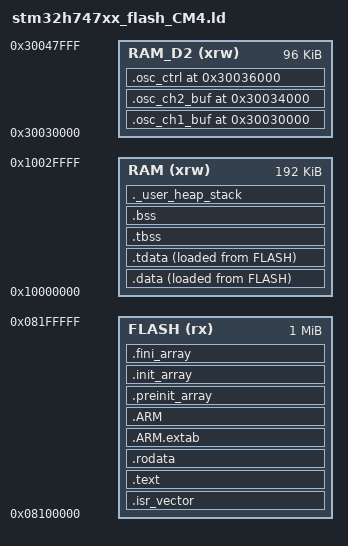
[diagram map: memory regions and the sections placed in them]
/*
******************************************************************************
**

**  File        : LinkerScript.ld
**
**
**  Abstract    : Linker script for STM32H7 series
**                1024Kbytes FLASH and 288Kbytes RAM
**
**                Set heap size, stack size and stack location according
**                to application requirements.
**
**                Set memory bank area and size if external memory is used.
**
**  Target      : STMicroelectronics STM32
**
**  Distribution: The file is distributed as is without any warranty
**                of any kind.
**
*****************************************************************************
** @attention
**
** Copyright (c) 2019 STMicroelectronics.
** All rights reserved.
**
** This software is licensed under terms that can be found in the LICENSE file
** in the root directory of this software component.
** If no LICENSE file comes with this software, it is provided AS-IS.
**
******************************************************************************
*/

/* Entry Point */
ENTRY(Reset_Handler)


/* Specify the memory areas */
MEMORY
{
FLASH (rx)      : ORIGIN = 0x08100000, LENGTH = 1024K
RAM (xrw)      : ORIGIN = 0x10000000, LENGTH = 192K
RAM_D2 (xrw)    : ORIGIN = 0x30030000, LENGTH = 96K
}
/* Highest address of the user mode stack */
_estack = 0x10030000;    /* end of RAM */
/* Generate a link error if heap and stack don't fit into RAM */
_Min_Heap_Size = 0x200;      /* required amount of heap  */
_Min_Stack_Size = 0x400; /* required amount of stack */

/* Define output sections */
SECTIONS
{
  /* The startup code goes first into FLASH */
  .isr_vector :
  {
    . = ALIGN(4);
    KEEP(*(.isr_vector)) /* Startup code */
    . = ALIGN(4);
  } >FLASH

  /* The program code and other data goes into FLASH */
  .text :
  {
    . = ALIGN(4);
    *(.text)           /* .text sections (code) */
    *(.text*)          /* .text* sections (code) */
    *(.glue_7)         /* glue arm to thumb code */
    *(.glue_7t)        /* glue thumb to arm code */
    *(.eh_frame)

    KEEP (*(.init))
    KEEP (*(.fini))

    . = ALIGN(4);
    _etext = .;        /* define a global symbols at end of code */
  } >FLASH

  /* Constant data goes into FLASH */
  .rodata :
  {
    . = ALIGN(4);
    *(.rodata)         /* .rodata sections (constants, strings, etc.) */
    *(.rodata*)        /* .rodata* sections (constants, strings, etc.) */
    . = ALIGN(4);
  } >FLASH

  .ARM.extab (READONLY) : /* The READONLY keyword is only supported in GCC11 and later, remove it if using GCC10 or earlier. */
  {
    *(.ARM.extab* .gnu.linkonce.armextab.*)
  } >FLASH
  .ARM (READONLY) : /* The READONLY keyword is only supported in GCC11 and later, remove it if using GCC10 or earlier. */
  {
    __exidx_start = .;
    *(.ARM.exidx*)
    __exidx_end = .;
  } >FLASH

  .preinit_array (READONLY) : /* The READONLY keyword is only supported in GCC11 and later, remove it if using GCC10 or earlier. */
  {
    PROVIDE_HIDDEN (__preinit_array_start = .);
    KEEP (*(.preinit_array*))
    PROVIDE_HIDDEN (__preinit_array_end = .);
  } >FLASH
  .init_array (READONLY) : /* The READONLY keyword is only supported in GCC11 and later, remove it if using GCC10 or earlier. */
  {
    PROVIDE_HIDDEN (__init_array_start = .);
    KEEP (*(SORT(.init_array.*)))
    KEEP (*(.init_array*))
    PROVIDE_HIDDEN (__init_array_end = .);
  } >FLASH
  .fini_array (READONLY) : /* The READONLY keyword is only supported in GCC11 and later, remove it if using GCC10 or earlier. */
  {
    PROVIDE_HIDDEN (__fini_array_start = .);
    KEEP (*(SORT(.fini_array.*)))
    KEEP (*(.fini_array*))
    PROVIDE_HIDDEN (__fini_array_end = .);
  } >FLASH

  /* used by the startup to initialize data */
  _sidata = LOADADDR(.data);

  /* Initialized data sections goes into RAM, load LMA copy after code */
  .data : 
  {
    . = ALIGN(4);
    _sdata = .;        /* create a global symbol at data start */
    *(.data)           /* .data sections */
    *(.data*)          /* .data* sections */

    . = ALIGN(4);
  } >RAM AT> FLASH

  /* Initialized TLS data section */
  .tdata : ALIGN(4)
  {
    *(.tdata .tdata.* .gnu.linkonce.td.*)
    . = ALIGN(4);
    _edata = .;        /* define a global symbol at data end */
    PROVIDE(__data_end = .);
    PROVIDE(__tdata_end = .);
  } >RAM AT> FLASH

  PROVIDE( __tdata_start = ADDR(.tdata) );
  PROVIDE( __tdata_size = __tdata_end - __tdata_start );

  PROVIDE( __data_start = ADDR(.data) );
  PROVIDE( __data_size = __data_end - __data_start );

  PROVIDE( __tdata_source = LOADADDR(.tdata) );
  PROVIDE( __tdata_source_end = LOADADDR(.tdata) + SIZEOF(.tdata) );
  PROVIDE( __tdata_source_size = __tdata_source_end - __tdata_source );

  PROVIDE( __data_source = LOADADDR(.data) );
  PROVIDE( __data_source_end = __tdata_source_end );
  PROVIDE( __data_source_size = __data_source_end - __data_source );


  
  /* Uninitialized data section */
  /* Uninitialized TLS data section */
  .tbss (NOLOAD) : ALIGN(4)
  {
    _sbss = .;         /* define a global symbol at bss start */
    __bss_start__ = _sbss;
    *(.tbss .tbss.*)
    . = ALIGN(4);
    PROVIDE( __tbss_end = . );
  } >RAM

  PROVIDE( __tbss_start = ADDR(.tbss) );
  PROVIDE( __tbss_size = __tbss_end - __tbss_start );
  PROVIDE( __tbss_offset = ADDR(.tbss) - ADDR(.tdata) );

  PROVIDE( __tls_base = __tdata_start );
  PROVIDE( __tls_end = __tbss_end );
  PROVIDE( __tls_size = __tls_end - __tls_base );
  PROVIDE( __tls_align = MAX(ALIGNOF(.tdata), ALIGNOF(.tbss)) );
  PROVIDE( __tls_size_align = (__tls_size + __tls_align - 1) & ~(__tls_align - 1) );
  PROVIDE( __arm32_tls_tcb_offset = MAX(8, __tls_align) );
  PROVIDE( __arm64_tls_tcb_offset = MAX(16, __tls_align) );

  .bss (NOLOAD) : ALIGN(4)
  {
    /* This is used by the startup in order to initialize the .bss section */
    *(.bss)
    *(.bss*)
    *(COMMON)

    . = ALIGN(4);
    _ebss = .;         /* define a global symbol at bss end */
    __bss_end__ = _ebss;
      PROVIDE( __bss_end = .);
  } >RAM
  PROVIDE( __non_tls_bss_start = ADDR(.bss) );

  PROVIDE( __bss_start = __tbss_start );
  PROVIDE( __bss_size = __bss_end - __bss_start );


  /* User_heap_stack section, used to check that there is enough RAM left */
  ._user_heap_stack (NOLOAD) :
  {
    . = ALIGN(8);
    PROVIDE ( end = . );
    PROVIDE ( _end = . );
    . = . + _Min_Heap_Size;
    . = . + _Min_Stack_Size;
    . = ALIGN(8);
  } >RAM

  /* 跨核共享缓冲 —— 三个对象的地址是 CM7 那边的硬契约 (见 sharedconfig.h
   * 的文件头), 所以在这里用绝对地址钉死。
   *
   * 原来这三个是共用一个 .dma_buffer 段、靠"谁先声明谁在前"排出来的。那个
   * 顺序由编译器决定, 换个优化级别就可能翻个个儿 —— -O2 下 GCC 就把 osc_ctrl
   * 排到了最前面, 于是 OSC_CH_Init 里的地址自检直接 Error_Handler。改成写死
   * 绝对地址之后, 优化级别再变也影响不到这里。
   *
   * 尺寸对不上会在链接期报错 (osc_ch1_buf 必须是 16 KB、osc_ch2_buf 8 KB、
   * osc_ctrl 128 B —— 0x30036000..0x30036080 正好顶到 CM7 那边的
   * LOG_CTRL_ADDR, 首尾正好接上), 不会悄悄错位。 */
  .osc_ch1_buf 0x30030000 (NOLOAD) : { KEEP(*(.osc_ch1_buf)) } >RAM_D2
  .osc_ch2_buf 0x30034000 (NOLOAD) : { KEEP(*(.osc_ch2_buf)) } >RAM_D2
  .osc_ctrl    0x30036000 (NOLOAD) : { KEEP(*(.osc_ctrl))    } >RAM_D2

  /* Remove information from the standard libraries */
  /DISCARD/ :
  {
    libc.a:* ( * )
    libm.a:* ( * )
    libgcc.a:* ( * )
  }

  .ARM.attributes 0 : { *(.ARM.attributes) }
}


